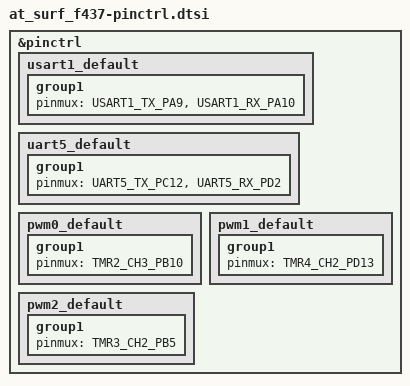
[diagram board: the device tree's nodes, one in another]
/*
 * Copyright (c) 2022, YuLong Yao <feilongphone@gmail.com>
 * SPDX-License-Identifier: Apache-2.0
 */

#include <dt-bindings/pinctrl/at32f437z(c-g-m)xx-pinctrl.h>

&pinctrl {
	usart1_default: usart1_default {
		group1 {
			pinmux = <USART1_TX_PA9>, <USART1_RX_PA10>;
		};
	};

	uart5_default: uart5_default {
		group1 {
			pinmux = <UART5_TX_PC12>, <UART5_RX_PD2>;
		};
	};

	pwm0_default: pwm0_default {
		group1 {
			pinmux = <TMR2_CH3_PB10>;
		};
	};

	pwm1_default: pwm1_default {
		group1 {
			pinmux = <TMR4_CH2_PD13>;
		};
	};

	pwm2_default: pwm2_default {
		group1 {
			pinmux = <TMR3_CH2_PB5>;
		};
	};
};
